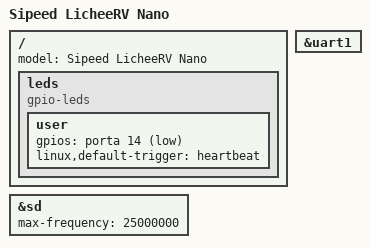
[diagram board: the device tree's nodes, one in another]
/dts-v1/;
#include "cv181x_base_riscv.dtsi"
#include "cv181x_asic_qfn.dtsi"
#include "cv181x_asic_sd.dtsi"
#include "cv181x_default_memmap.dtsi"

// The Nano exposes UART1, a user LED and a user button. Wireless variants
// require a separate SDIO wireless driver/firmware integration.
&uart1 { status = "okay"; };
&sd { max-frequency = <25000000>; };

/ {
	model = "Sipeed LicheeRV Nano";
	/delete-node/ wifi_pin;
	/delete-node/ bt_pin;
	leds {
		compatible = "gpio-leds";
		user {
			gpios = <&porta 14 GPIO_ACTIVE_LOW>;
			linux,default-trigger = "heartbeat";
		};
	};
};


#include "magnesium-headless.dtsi"
#include "magnesium-cv181x-headless.dtsi"
